# AE722F80F55D5LS_CM55_HP_View register map
Vendor: Alif Semiconductor; Series: E7; File version: 1.0
CPU: CM55 r1p0, selectable endian, MPU, FPU, double-precision FPU, DSP, VTOR, 8 interrupt priority bits, 1 SAU regions
Registers are 32-bit, read-write, reset 0x0 unless marked. A register's access mark holds for its fields unless they carry their own. Offsets are from the block's base; [hi:lo] are bit positions; 'fields as' and 'values as' point back to an identical list.

## REFCLK_CNTRead
Base 0x1A210000
Same registers: S32K_CNTRead 0x1A410000
0x00 CNTCVL ro reset not defined — Read-only Version of CNTCVL Register
  [31:0] COUNTVALUE_LO — Read-only version of CNTCVL register.
0x04 CNTCVH ro reset not defined — Read-only Version of CNTCVH Register
  [31:0] COUNTVALUE_HI — Read-only version of CNTCVH register

## WDT_AP_CTRL
Base 0x1A300000
Same registers: WDT_AP_REFRESH 0x1A310000, WDT_AP_S_CTRL 0x1A320000, WDT_AP_S_REFRESH 0x1A330000
0x00 WDT_WRR wo — Watchdog Refresh Register
  [31:0] WRR — A write to this register causes the watchdog to refresh and start a new watch period. A read has no effect and returns 0.
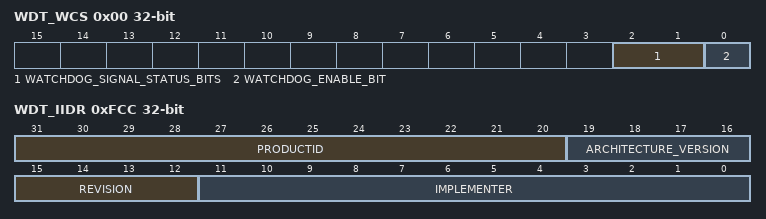
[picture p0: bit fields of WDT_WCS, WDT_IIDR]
0x00 WDT_WCS (alternate view of WDT_WRR) — Watchdog Control and Status Register
  [2:1] WATCHDOG_SIGNAL_STATUS_BITS ro — A read of this bit field indicates the current state of the watchdog signals. A write to these bits has no effect. Bit [2] reflects the status of WDT_AP_IRQ1 and bit [1] reflects the status of WDT_AP_IRQ0.
  [0] WATCHDOG_ENABLE_BIT — A read of this bit indicates the current enabled or disabled state of the watchdog. This bit resets to 0 on watchdog cold reset.
    0=The watchdog is disabled; 1=The watchdog is enabled
0x08 WDT_WOR — Watchdog Offset Register
  [31:0] WOR — 32-bit unsigned watchdog countdown timer value.
0x10 WDT_WCV_31_0 — Watchdog Compare Value Register, lower bits
  [31:0] WCV_31_0 — The lower 32 bits of the current watchdog compare value.
0x14 WDT_WCV_63_32 — Watchdog Compare Value Register, upper bits
  [31:0] WCV_63_32 — The upper 32 bits of the current watchdog compare value.
0xFCC WDT_IIDR ro — Interface Identification Register
  [31:20] PRODUCTID — Implementation defined product identifier
  [19:16] ARCHITECTURE_VERSION — WDT architecture version
  [15:12] REVISION — Implementation defined component revision number
  [11:0] IMPLEMENTER — Implementer JEP106 code

## CGU
Base 0x1A602000
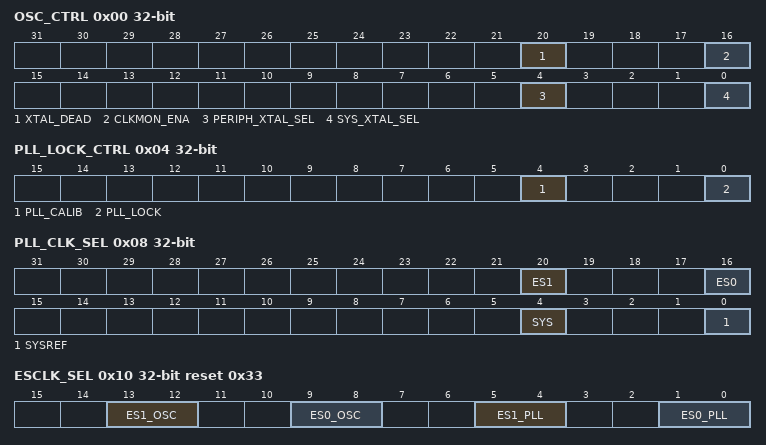
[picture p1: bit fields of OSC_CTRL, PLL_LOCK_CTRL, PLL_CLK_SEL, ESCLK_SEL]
0x00 OSC_CTRL — Oscillator Control Register
  [20] XTAL_DEAD ro — 38.4 MHz crystal-oscillator clock monitor status
    0=No crystal clock dead found; 1=Crystal clock dead detected
  [16] CLKMON_ENA — Enable 38.4 MHz crystal-oscillator clock monitor
    0=Disable clock monitor; 1=Enable clock monitor
  [4] PERIPH_XTAL_SEL — Select oscillator clock source for HFOSC_CLK
    0=Select 38.4 MHz (76.8 MHz / 2) ring-oscillator clock; 1=Select 38.4 MHz crystal-oscillator clock
  [0] SYS_XTAL_SEL — Select oscillator clock source for CPUPLL_CLK, SYSPLL_CLK, and SYST_REFCLK
    0=Select 76.8 MHz ring-oscillator clock; 1=Select 38.4 MHz crystal-oscillator clock
0x04 PLL_LOCK_CTRL — PLL Lock Control Register
  [4] PLL_CALIB ro — PLL calibration status
    0=PLL not in calibration; 1=PLL in calibration
  [0] PLL_LOCK — PLL lock control
    0=PLL not locked; 1=PLL locked
0x08 PLL_CLK_SEL — PLL Clock Select Register
  [20] ES1 — Select the source for RTSS_HE_CLK
    0=Select a value specified by the ESCLK_SEL[ES1_OSC] field; 1=Select a value specified by the ESCLK_SEL[ES1_PLL] field
  [16] ES0 — Select the source for RTSS_HP_CLK
    0=Select a value specified by the ESCLK_SEL[ES0_OSC] field; 1=Select a value specified by the ESCLK_SEL[ES0_PLL] field
  [4] SYS — Select the source for CPUPLL_CLK and SYSPLL_CLK
    0=Select oscillator clock source; 1=Select PLL clock source
  [0] SYSREF — Select the source for SYST_REFCLK
    0=Select oscillator clock source; 1=Select PLL clock source
0x10 ESCLK_SEL reset 0x33 — Clock Select Register for M55-HP and M55-HE
  [13:12] ES1_OSC — Select oscillator clock frequency for RTSS_HE_CLK
    0=Select 76.8 MHz ring-oscillator clock; 1=Select 38.4 MHz ring-oscillator clock; 2=Select 76.8 MHz crystal-oscillator clock; 3=Select 38.4 MHz crystal-oscillator clock
  [9:8] ES0_OSC — Select oscillator clock frequency for RTSS_HP_CLK
    values as ES1_OSC
  [5:4] ES1_PLL — Select PLL clock frequency for RTSS_HE_CLK
    0=Select 80 MHz PLL clock; 1=Select 80 MHz PLL clock; 2=Select 160 MHz PLL clock; 3=Select 160 MHz PLL clock
  [1:0] ES0_PLL — Select PLL clock frequency for RTSS_HP_CLK
    0=Select 100 MHz PLL clock; 1=Select 200 MHz PLL clock; 3=Select 400 MHz PLL clock
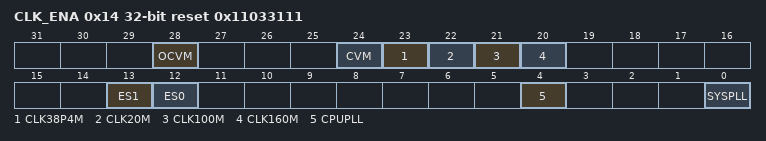
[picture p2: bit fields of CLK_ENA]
0x14 CLK_ENA reset 0x11033111 — Clock Enable Register
  [all] fields
    0=Disable clock; 1=Enable clock
  [28] OCVM — Enable SRAM1 clock
  [24] CVM — Enable SRAM0 clock
  [23] CLK38P4M — Enable HFOSC_CLK
  [22] CLK20M — Enable USB_CLK and 10M_CLK
  [21] CLK100M — Enable 100M_CLK
  [20] CLK160M — Enable PERIPH_CLK
  [13] ES1 — Enable RTSS_HE_CLK
  [12] ES0 — Enable RTSS_HP_CLK
  [4] CPUPLL — Enable CPUPLL_CLK
  [0] SYSPLL — Enable SYSPLL_CLK
0x20 CGU_IRQ ro — CGU Interrupt Status Register
  [0] XTAL_DEAD read-clears — 38.4 MHz crystal-oscillator dead. Active high, read to clear. Note: The XTAL_DEAD interrupt is mapped to the Secure Enclave.
